# NUC1311AE_v1 register map
File version: 1.0
Registers are 32-bit, read-write, reset 0x0 unless marked. A register's access mark holds for its fields unless they carry their own. Offsets are from the block's base; [hi:lo] are bit positions; {n}, {i} and the like mark numbered series; 'fields as' and 'values as' point back to an identical list.

## GPIO — GPIO Register Map
Base 0x50004000
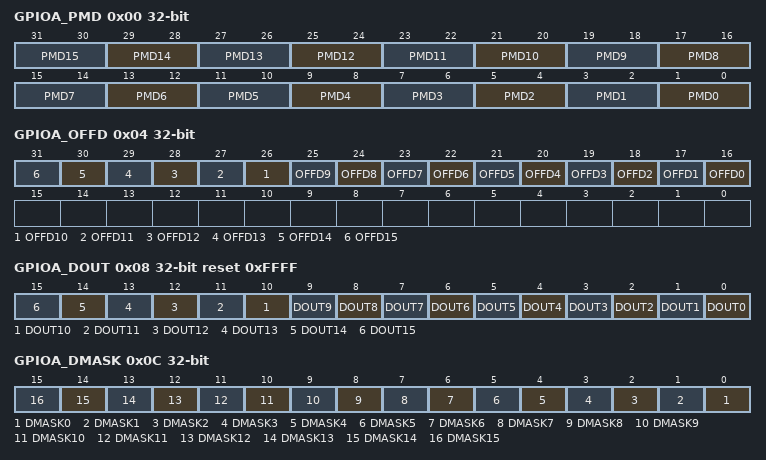
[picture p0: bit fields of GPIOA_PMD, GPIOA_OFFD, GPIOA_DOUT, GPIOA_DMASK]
0x00 GPIOA_PMD reset not defined — GPIO Port A Pin I/O Mode Control
  [all] fields
    0=GPIO port [n] pin is in Input mode; 1=GPIO port [n] pin is in Push-pull Output mode; 2=GPIO port [n] pin is in Open-drain Output mode; 3=GPIO port [n] pin is in Quasi-bidirectional mode
  [2n+1:2n] PMD{n} (n=0..15) — GPIOx I/O Pin[N] Mode Control. Determine each I/O mode of GPIOx pins. Note2: The initial value of this field is defined by CIOINI (CONFIG0[10]). If CIOINI is set to 1, the default value is 0xFFFF_FFFF and all pins will be Quasi-bidirectional mode after chip is powered on. If CIOINI is cleared to 0, the default value is 0x0000_0000 and all pins will be input only mode after chip is powered on.
0x04 GPIOA_OFFD — GPIO Port A Pin Digital Input Path Disable Control
  [all] fields
    0=I/O digital input path Enabled; 1=I/O digital input path Disabled (digital input tied to low)
  [n+16] OFFD{n} (n=0..15) — GPIOx Pin[N] Digital Input Path Disable Control. Each of these bits is used to control if the digital input path of corresponding GPIO pin is disabled. If input is analog signal, users can disable GPIO digital input path to avoid current leakage.
0x08 GPIOA_DOUT reset 0xFFFF — GPIO Port A Data Output Value
  [all] fields
    0=GPIO port [A/B/C/D/E/F] Pin[n] will drive Low if the GPIO pin is configured as Push-pull output, Open-drain output or Quasi-bidirectional mode; 1=GPIO port [A/B/C/D/E/F] Pin[n] will drive High if the GPIO pin is configured as Push-pull output or Quasi-bidirectional mode
  [n] DOUT{n} (n=0..15) — GPIOx Pin[N] Output Value. Each of these bits controls the status of a GPIO pin when the GPIO pin is configured as Push-pull output, open-drain output or quasi-bidirectional mode.
0x0C GPIOA_DMASK — GPIO Port A Data Output Write Mask
  [all] fields
    0=Corresponding GPIOx_DOUT[n] bit can be updated; 1=Corresponding GPIOx_DOUT[n] bit protected
  [n] DMASK{n} (n=0..15) — Port [A/B/C/D/E/F] Data Output Write Mask. These bits are used to protect the corresponding register of GPIOx_DOUT[n] bit. When the DMASK[n] bit is set to 1, the corresponding GPIOx_DOUT[n] bit is protected. If the write signal is masked, write data to the protect bit is ignored.
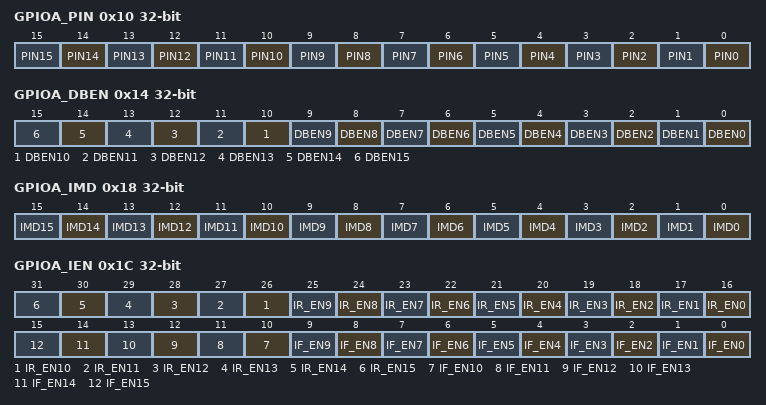
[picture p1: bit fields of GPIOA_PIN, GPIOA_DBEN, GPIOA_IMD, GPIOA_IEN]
0x10 GPIOA_PIN ro (reset mask 0xFFFF0000) — GPIO Port A Pin Value
  [n] PIN{n} (n=0..15) — Port [A/B/C/D/E/F] Pin Values. Each bit of the register reflects the actual status of the respective GPIO pin. If the bit is 1, it indicates the corresponding pin status is high, else the pin status is low. Note:
0x14 GPIOA_DBEN — GPIO Port A De-bounce Enable
  [all] fields
    0=Bit[n] de-bounce function Disabled; 1=Bit[n] de-bounce function Enabled
  [n] DBEN{n} (n=0..15) — Port [A/B/C/D/E/F] Input Signal De-Bounce Enable Control. DBEN[n] is used to enable the de-bounce function for each corresponding bit. If the input signal pulse width cannot be sampled by continuous two de-bounce sample cycle, the input signal transition is seen as the signal bounce and will not trigger the interrupt. The de-bounce clock source is controlled by DBNCECON[4], one de-bounce sample cycle period is controlled by DBNCECON[3:0].
0x18 GPIOA_IMD — GPIO Port A Interrupt Mode Control
  [all] fields
    0=Edge trigger interrupt; 1=Level trigger interrupt
  [n] IMD{n} (n=0..15) — Port [A/B/C/D/E/F] Edge Or Level Detection Interrupt Control. IMD[n] is used to control the interrupt is by level trigger or by edge trigger. If the interrupt is by edge trigger, the trigger source can be controlled by de-bounce. If the interrupt is by level trigger, the input source is sampled by one HCLK clock and generates the interrupt.
0x1C GPIOA_IEN — GPIO Port A Interrupt Enable
  [n+16] IR_EN{n} (n=0..15) — Port [A/B/C/D/E/F] Interrupt Enabled By Input Rising Edge Or Input Level High. IR_EN[n] used to enable the interrupt for each of the corresponding input GPIO_PIN[n]. Set bit to 1 also enable the pin wake-up function. When setting the IR_EN[n] bit to 1: If the interrupt is level trigger, the input PIN[n] state at level 'high' will generate the interrupt. If the interrupt is edge trigger, the input PIN[n] state change from 'low-to-high' will generate the interrupt.
    0=PIN[n] level-high or low-to-high interrupt Disabled; 1=PIN[n] level-high or low-to-high interrupt Enabled
  [n] IF_EN{n} (n=0..15) — Port [A/B/C/D/E/F] Interrupt Enabled By Input Falling Edge Or Input Level Low. IF_EN[n] is used to enable the interrupt for each of the corresponding input GPIO_PIN[n]. Set bit to 1 also enable the pin wake-up function. When setting the IF_EN[n] bit to 1: If the interrupt is level trigger, the input PIN[n] state at level 'low' will generate the interrupt. If the interrupt is edge trigger, the input PIN[n] state change from 'high-to-low' will generate the interrupt.
    0=PIN[n] state low-level or high-to-low change interrupt Disabled; 1=PIN[n] state low-level or high-to-low change interrupt Enabled
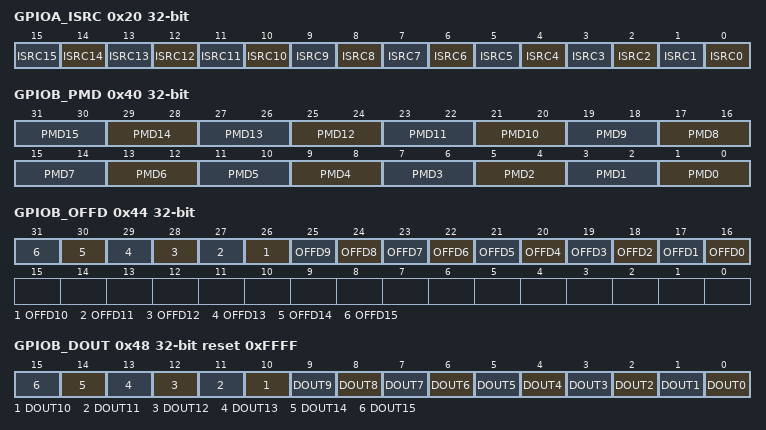
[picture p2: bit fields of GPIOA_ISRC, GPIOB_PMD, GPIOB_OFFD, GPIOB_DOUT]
0x20 GPIOA_ISRC — GPIO Port A Interrupt Source Flag
  [all] fields
    0=No interrupt at GPIOx[n]. No action; 1=GPIOx[n] generates an interrupt. Clear the corresponding pending interrupt
  [n] ISRC{n} (n=0..15) — Port [A/B/C/D/E/F] Interrupt Source Flag. Read :
0x40 GPIOB_PMD reset not defined — GPIO Port B Pin I/O Mode Control
  fields as GPIOA_PMD
0x44 GPIOB_OFFD — GPIO Port B Pin Digital Input Path Disable Control
  fields as GPIOA_OFFD
0x48 GPIOB_DOUT reset 0xFFFF — GPIO Port B Data Output Value
  fields as GPIOA_DOUT
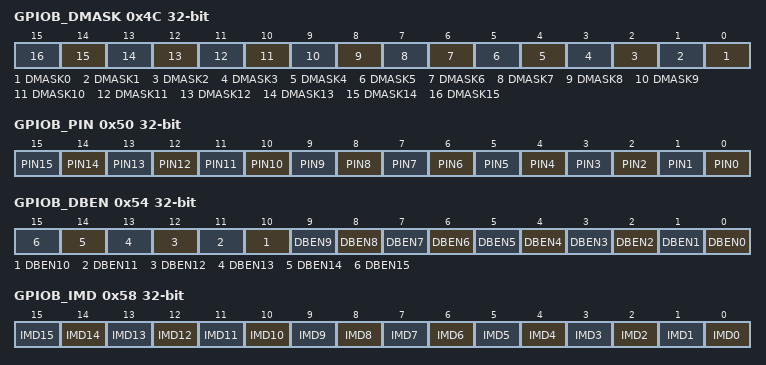
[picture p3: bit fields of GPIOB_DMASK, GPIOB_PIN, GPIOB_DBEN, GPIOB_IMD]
0x4C GPIOB_DMASK — GPIO Port B Data Output Write Mask
  fields as GPIOA_DMASK
0x50 GPIOB_PIN ro (reset mask 0xFFFF0000) — GPIO Port B Pin Value
  fields as GPIOA_PIN
0x54 GPIOB_DBEN — GPIO Port B De-bounce Enable
  fields as GPIOA_DBEN
0x58 GPIOB_IMD — GPIO Port B Interrupt Mode Control
  fields as GPIOA_IMD
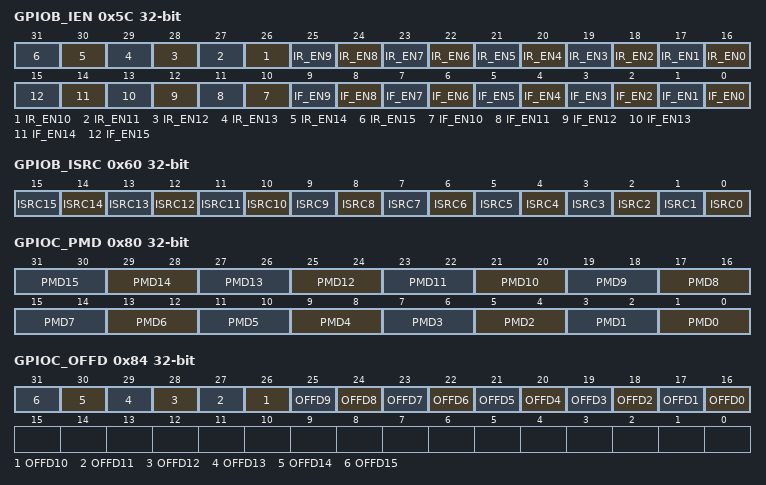
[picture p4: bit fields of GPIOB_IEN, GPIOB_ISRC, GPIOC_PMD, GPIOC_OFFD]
0x5C GPIOB_IEN — GPIO Port B Interrupt Enable
  fields as GPIOA_IEN
0x60 GPIOB_ISRC — GPIO Port B Interrupt Source Flag
  fields as GPIOA_ISRC
0x80 GPIOC_PMD reset not defined — GPIO Port C Pin I/O Mode Control
  fields as GPIOA_PMD
0x84 GPIOC_OFFD — GPIO Port C Pin Digital Input Path Disable Control
  fields as GPIOA_OFFD
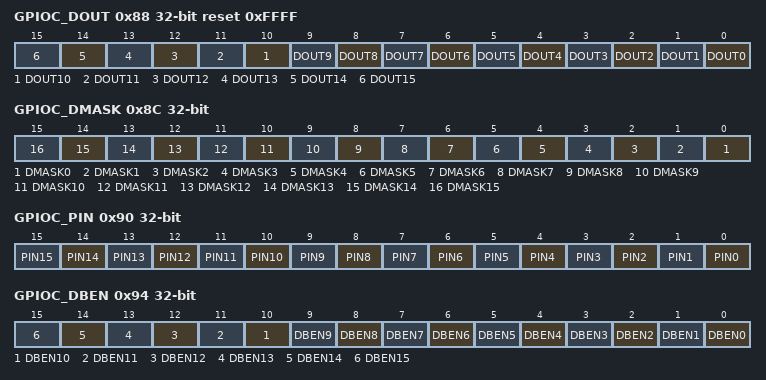
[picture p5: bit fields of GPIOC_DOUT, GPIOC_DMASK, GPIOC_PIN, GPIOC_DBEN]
0x88 GPIOC_DOUT reset 0xFFFF — GPIO Port C Data Output Value
  fields as GPIOA_DOUT
0x8C GPIOC_DMASK — GPIO Port C Data Output Write Mask
  fields as GPIOA_DMASK
0x90 GPIOC_PIN ro (reset mask 0xFFFF0000) — GPIO Port C Pin Value
  fields as GPIOA_PIN
0x94 GPIOC_DBEN — GPIO Port C De-bounce Enable
  fields as GPIOA_DBEN
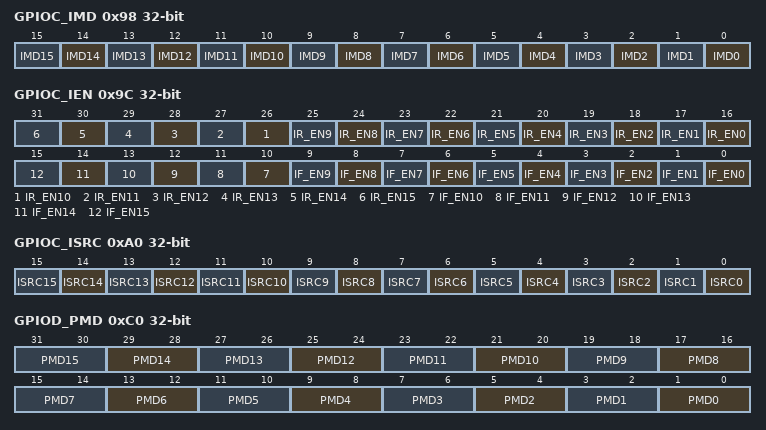
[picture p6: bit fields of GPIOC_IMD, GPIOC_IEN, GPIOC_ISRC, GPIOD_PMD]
0x98 GPIOC_IMD — GPIO Port C Interrupt Mode Control
  fields as GPIOA_IMD
0x9C GPIOC_IEN — GPIO Port C Interrupt Enable
  fields as GPIOA_IEN
0xA0 GPIOC_ISRC — GPIO Port C Interrupt Source Flag
  fields as GPIOA_ISRC
0xC0 GPIOD_PMD reset not defined — GPIO Port D Pin I/O Mode Control
  fields as GPIOA_PMD
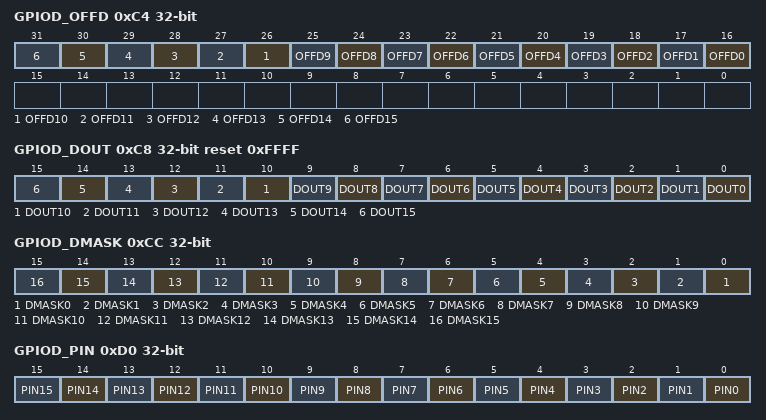
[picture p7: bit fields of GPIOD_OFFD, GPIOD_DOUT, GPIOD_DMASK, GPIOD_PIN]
0xC4 GPIOD_OFFD — GPIO Port D Pin Digital Input Path Disable Control
  fields as GPIOA_OFFD
0xC8 GPIOD_DOUT reset 0xFFFF — GPIO Port D Data Output Value
  fields as GPIOA_DOUT
0xCC GPIOD_DMASK — GPIO Port D Data Output Write Mask
  fields as GPIOA_DMASK
0xD0 GPIOD_PIN ro (reset mask 0xFFFF0000) — GPIO Port D Pin Value
  fields as GPIOA_PIN
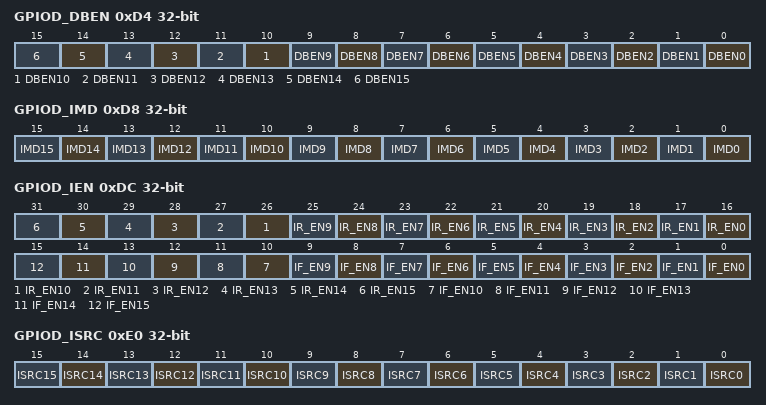
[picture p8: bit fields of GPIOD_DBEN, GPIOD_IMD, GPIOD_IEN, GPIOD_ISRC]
0xD4 GPIOD_DBEN — GPIO Port D De-bounce Enable
  fields as GPIOA_DBEN
0xD8 GPIOD_IMD — GPIO Port D Interrupt Mode Control
  fields as GPIOA_IMD
0xDC GPIOD_IEN — GPIO Port D Interrupt Enable
  fields as GPIOA_IEN
0xE0 GPIOD_ISRC — GPIO Port D Interrupt Source Flag
  fields as GPIOA_ISRC
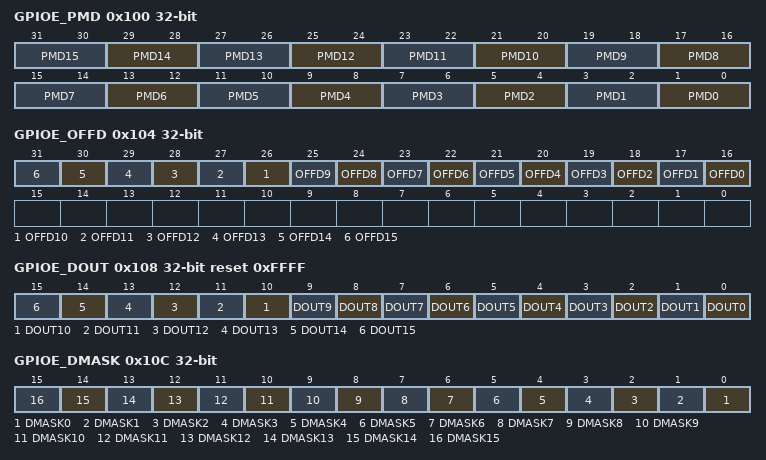
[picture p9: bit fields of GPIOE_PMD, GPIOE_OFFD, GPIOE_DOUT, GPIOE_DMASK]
0x100 GPIOE_PMD reset not defined — GPIO Port E Pin I/O Mode Control
  fields as GPIOA_PMD
0x104 GPIOE_OFFD — GPIO Port E Pin Digital Input Path Disable Control
  fields as GPIOA_OFFD
0x108 GPIOE_DOUT reset 0xFFFF — GPIO Port E Data Output Value
  fields as GPIOA_DOUT
0x10C GPIOE_DMASK — GPIO Port E Data Output Write Mask
  fields as GPIOA_DMASK
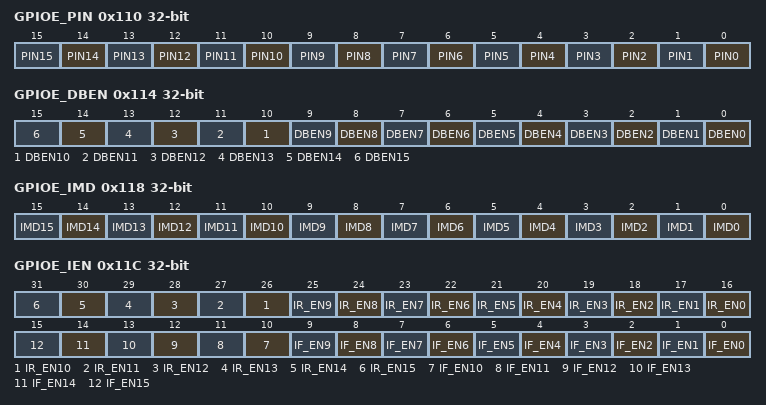
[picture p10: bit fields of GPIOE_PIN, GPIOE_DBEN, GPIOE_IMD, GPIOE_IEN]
0x110 GPIOE_PIN ro (reset mask 0xFFFF0000) — GPIO Port E Pin Value
  fields as GPIOA_PIN
0x114 GPIOE_DBEN — GPIO Port E De-bounce Enable
  fields as GPIOA_DBEN
0x118 GPIOE_IMD — GPIO Port E Interrupt Mode Control
  fields as GPIOA_IMD
0x11C GPIOE_IEN — GPIO Port E Interrupt Enable
  fields as GPIOA_IEN
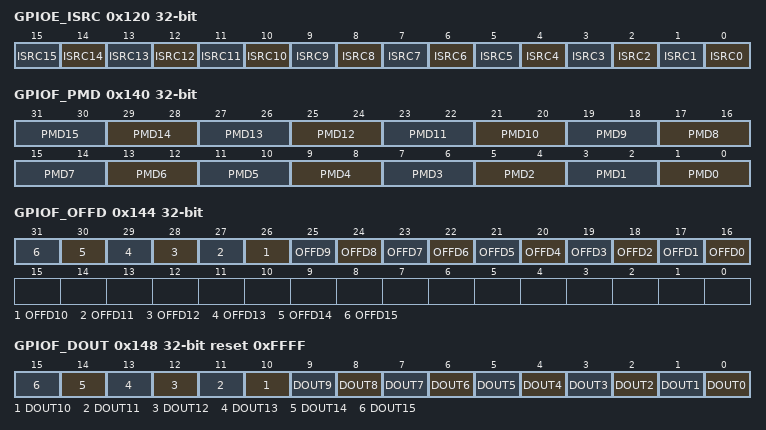
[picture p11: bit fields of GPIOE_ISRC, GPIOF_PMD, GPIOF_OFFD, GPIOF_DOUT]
0x120 GPIOE_ISRC — GPIO Port E Interrupt Source Flag
  fields as GPIOA_ISRC
0x140 GPIOF_PMD reset not defined — GPIO Port F Pin I/O Mode Control
  fields as GPIOA_PMD
0x144 GPIOF_OFFD — GPIO Port F Pin Digital Input Path Disable Control
  fields as GPIOA_OFFD
0x148 GPIOF_DOUT reset 0xFFFF — GPIO Port F Data Output Value
  fields as GPIOA_DOUT
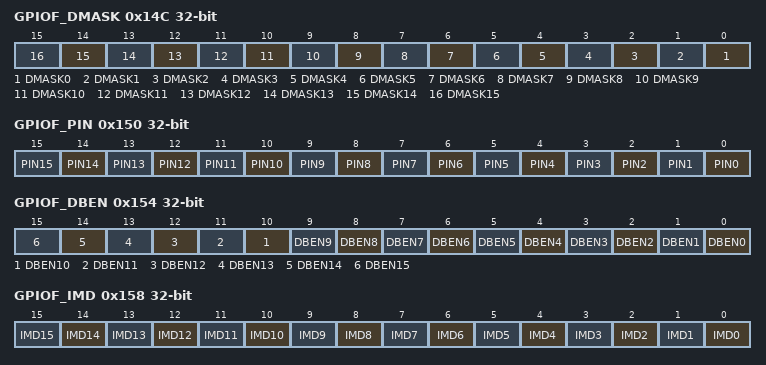
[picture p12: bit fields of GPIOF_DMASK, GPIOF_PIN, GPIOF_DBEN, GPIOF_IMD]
0x14C GPIOF_DMASK — GPIO Port F Data Output Write Mask
  fields as GPIOA_DMASK
0x150 GPIOF_PIN ro (reset mask 0xFFFF0000) — GPIO Port F Pin Value
  fields as GPIOA_PIN
0x154 GPIOF_DBEN — GPIO Port F De-bounce Enable
  fields as GPIOA_DBEN
0x158 GPIOF_IMD — GPIO Port F Interrupt Mode Control
  fields as GPIOA_IMD
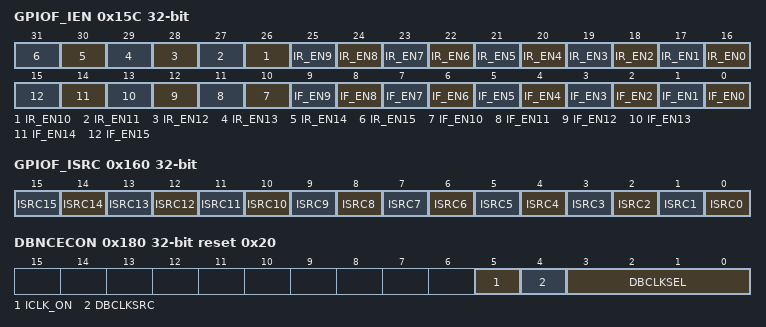
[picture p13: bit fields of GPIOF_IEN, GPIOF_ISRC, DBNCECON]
0x15C GPIOF_IEN — GPIO Port F Interrupt Enable
  fields as GPIOA_IEN
0x160 GPIOF_ISRC — GPIO Port F Interrupt Source Flag
  fields as GPIOA_ISRC
0x180 DBNCECON reset 0x20 — External Interrupt De-bounce Control
  [5] ICLK_ON — Interrupt Clock On Mode. It is recommended to disable this bit to save system power if no special application concern.
    0=Edge detection circuit is active only if I/O pin corresponding GPIOx_IEN bit is set to 1; 1=All I/O pins edge detection circuit is always active after reset
  [4] DBCLKSRC — De-Bounce Counter Clock Source Selection
    0=De-bounce counter clock source is the HCLK; 1=De-bounce counter clock source is the internal 10 kHz low speed oscillator
  [3:0] DBCLKSEL — De-Bounce Sampling Cycle Selection
{0x200+4i} PA{i}_PDIO (reset mask 0xFFFFFFF0) (i=0..15) — GPIO PA.n Pin Data Input/Output
  [0] Pxn_PDIO — GPIO Px.N Pin Data Input/Output. Write this bit can control one GPIO pin output value. Read this register to get GPIO pin status. For example: writing PA0_PDIO will reflect the written value to bit GPIOA_DOUT[0], read PA0_PDIO will return the value of GPIOA_PIN[0]. Note: The write operation will not be affected by register GPIOx_DMASK.
    0=Corresponding GPIO pin set to low; 1=Corresponding GPIO pin set to high
{0x240+4i} PB{i}_PDIO (reset mask 0xFFFFFFF0) (i=0..15) — GPIO PB.n Pin Data Input/Output
  fields as PA0_PDIO
{0x280+4i} PC{i}_PDIO (reset mask 0xFFFFFFF0) (i=0..3) — GPIO PC.n Pin Data Input/Output
  fields as PA0_PDIO
{0x280+4i} PC{i}_PDIO (reset mask 0xFFFFFFF0) (i=6..11) — GPIO PC.n Pin Data Input/Output
  fields as PA0_PDIO
0x2B8 PC14_PDIO (reset mask 0xFFFFFFF0) — GPIO PC.n Pin Data Input/Output
  fields as PA0_PDIO
0x2BC PC15_PDIO (reset mask 0xFFFFFFF0) — GPIO PC.n Pin Data Input/Output
  fields as PA0_PDIO
0x2D8 PD6_PDIO (reset mask 0xFFFFFFF0) — GPIO PD.n Pin Data Input/Output
  fields as PA0_PDIO
0x2DC PD7_PDIO (reset mask 0xFFFFFFF0) — GPIO PD.n Pin Data Input/Output
  fields as PA0_PDIO
0x2F8 PD14_PDIO (reset mask 0xFFFFFFF0) — GPIO PD.n Pin Data Input/Output
  fields as PA0_PDIO
0x2FC PD15_PDIO (reset mask 0xFFFFFFF0) — GPIO PD.n Pin Data Input/Output
  fields as PA0_PDIO
0x314 PE5_PDIO (reset mask 0xFFFFFFF0) — GPIO PE.n Pin Data Input/Output
  fields as PA0_PDIO
0x340 PF0_PDIO (reset mask 0xFFFFFFF0) — GPIO PF.n Pin Data Input/Output
  fields as PA0_PDIO
0x344 PF1_PDIO (reset mask 0xFFFFFFF0) — GPIO PF.n Pin Data Input/Output
  fields as PA0_PDIO
{0x340+4i} PF{i}_PDIO (reset mask 0xFFFFFFF0) (i=4..8) — GPIO PF.n Pin Data Input/Output
  fields as PA0_PDIO
